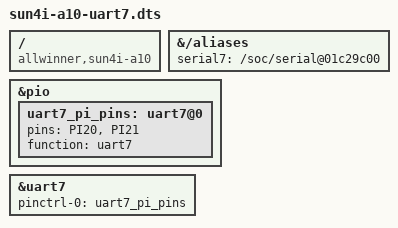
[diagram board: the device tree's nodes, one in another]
/dts-v1/;
/plugin/;

/ {
	compatible = "allwinner,sun4i-a10";

	fragment@0 {
		target-path = "/aliases";
		__overlay__ {
			serial7 = "/soc/serial@01c29c00";
		};
	};

	fragment@1 {
		target = <&pio>;
		__overlay__ {
			uart7_pi_pins: uart7@0 {
				pins = "PI20", "PI21";
				function = "uart7";
			};
		};
	};

	fragment@2 {
		target = <&uart7>;
		 __overlay__ {
			pinctrl-names = "default";
			pinctrl-0 = <&uart7_pi_pins>;
			status = "okay";
		};
	};
};
